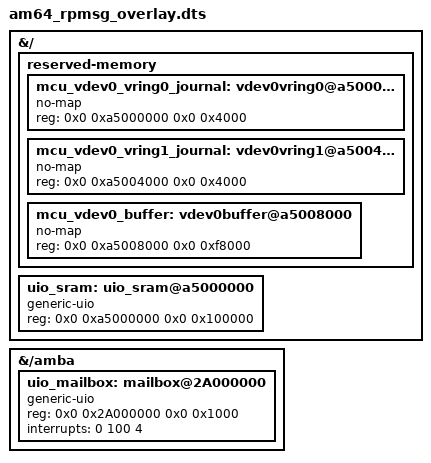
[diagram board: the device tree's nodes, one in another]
/dts-v1/;
/plugin/;

&{/} {
	reserved-memory {
		#address-cells = <2>;
		#size-cells = <2>;

		mcu_vdev0_vring0_journal: vdev0vring0@a5000000 {
			no-map;
			reg = <0x0 0xa5000000 0x0 0x4000>;
		};

		mcu_vdev0_vring1_journal: vdev0vring1@a5004000 {
			no-map;
			reg = <0x0 0xa5004000 0x0 0x4000>;
		};

		mcu_vdev0_buffer: vdev0buffer@a5008000 {
			no-map;
			reg = <0x0 0xa5008000 0x0 0xf8000>;
		};
	};

	uio_sram: uio_sram@a5000000 {
		compatible = "generic-uio";
		reg = <0x0 0xa5000000 0x0 0x100000>;
	};
};

&{/amba} { // Adjust based on ZynqMP base DTB
	uio_mailbox: mailbox@2A000000 {
		compatible = "generic-uio";
		reg = <0x0 0x2A000000 0x0 0x1000>;
		interrupts = <0 100 4>; // Mock IRQ
	};
};
